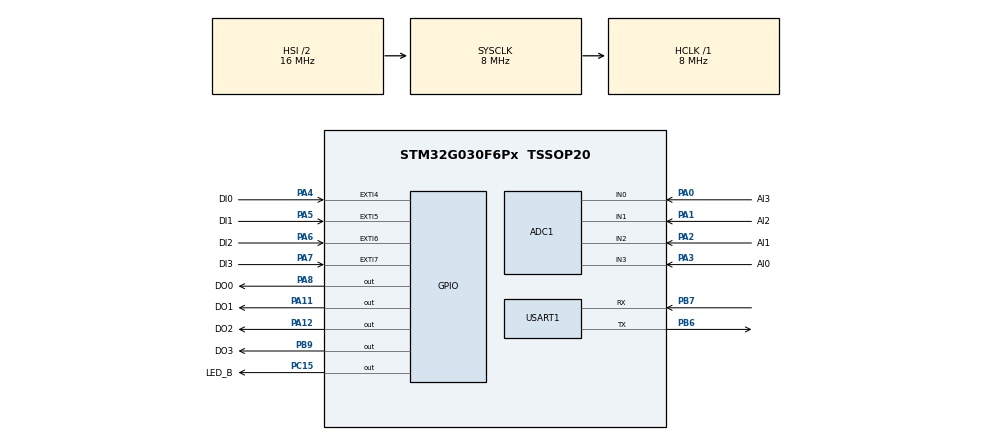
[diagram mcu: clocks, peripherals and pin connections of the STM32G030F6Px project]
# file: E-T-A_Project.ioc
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ADC1.Channel-0\#ChannelRegularConversion=ADC_CHANNEL_0
ADC1.Channel-1\#ChannelRegularConversion=ADC_CHANNEL_1
ADC1.Channel-2\#ChannelRegularConversion=ADC_CHANNEL_2
ADC1.Channel-3\#ChannelRegularConversion=ADC_CHANNEL_3
ADC1.ContinuousConvMode=DISABLE
ADC1.EnableAnalogWatchDog1=false
ADC1.NbrOfConversion=4
ADC1.NbrOfConversionFlag=1
ADC1.Rank-0\#ChannelRegularConversion=1
ADC1.Rank-1\#ChannelRegularConversion=2
ADC1.Rank-2\#ChannelRegularConversion=3
ADC1.Rank-3\#ChannelRegularConversion=4
ADC1.SamplingTime-0\#ChannelRegularConversion=ADC_SAMPLINGTIME_COMMON_1
ADC1.SamplingTime-1\#ChannelRegularConversion=ADC_SAMPLINGTIME_COMMON_1
ADC1.SamplingTime-2\#ChannelRegularConversion=ADC_SAMPLINGTIME_COMMON_1
ADC1.SamplingTime-3\#ChannelRegularConversion=ADC_SAMPLINGTIME_COMMON_1
ADC1.SamplingTimeCommon1=ADC_SAMPLETIME_12CYCLES_5
ADC1.SelectedChannel=ADC_CHANNEL_0|ADC_CHANNEL_1|ADC_CHANNEL_2|ADC_CHANNEL_3
ADC1.master=1
Dma.ADC1.0.Direction=DMA_PERIPH_TO_MEMORY
Dma.ADC1.0.EventEnable=DISABLE
Dma.ADC1.0.Instance=DMA1_Channel1
Dma.ADC1.0.MemDataAlignment=DMA_MDATAALIGN_HALFWORD
Dma.ADC1.0.MemInc=DMA_MINC_ENABLE
Dma.ADC1.0.Mode=DMA_CIRCULAR
Dma.ADC1.0.PeriphDataAlignment=DMA_PDATAALIGN_HALFWORD
Dma.ADC1.0.PeriphInc=DMA_PINC_DISABLE
Dma.ADC1.0.Polarity=HAL_DMAMUX_REQ_GEN_RISING
Dma.ADC1.0.Priority=DMA_PRIORITY_LOW
Dma.ADC1.0.RequestNumber=1
Dma.ADC1.0.SignalID=NONE
Dma.ADC1.0.SyncEnable=ENABLE
Dma.ADC1.0.SyncPolarity=HAL_DMAMUX_SYNC_RISING
Dma.ADC1.0.SyncRequestNumber=1
Dma.ADC1.0.SyncSignalID=HAL_DMAMUX1_SYNC_TIM14_OC
Dma.Request0=ADC1
Dma.Request1=USART1_RX
Dma.USART1_RX.1.Direction=DMA_PERIPH_TO_MEMORY
Dma.USART1_RX.1.EventEnable=DISABLE
Dma.USART1_RX.1.Instance=DMA1_Channel2
Dma.USART1_RX.1.MemDataAlignment=DMA_MDATAALIGN_BYTE
Dma.USART1_RX.1.MemInc=DMA_MINC_ENABLE
Dma.USART1_RX.1.Mode=DMA_CIRCULAR
Dma.USART1_RX.1.PeriphDataAlignment=DMA_PDATAALIGN_BYTE
Dma.USART1_RX.1.PeriphInc=DMA_PINC_DISABLE
Dma.USART1_RX.1.Polarity=HAL_DMAMUX_REQ_GEN_RISING
Dma.USART1_RX.1.Priority=DMA_PRIORITY_LOW
Dma.USART1_RX.1.RequestNumber=1
Dma.USART1_RX.1.SignalID=NONE
Dma.USART1_RX.1.SyncEnable=DISABLE
Dma.USART1_RX.1.SyncPolarity=HAL_DMAMUX_SYNC_NO_EVENT
Dma.USART1_RX.1.SyncRequestNumber=1
Dma.USART1_RX.1.SyncSignalID=NONE
Mcu.Family=STM32G0
Mcu.Name=STM32G030F6Px
Mcu.Package=TSSOP20
NVIC.DMA1_Ch4_5_DMAMUX1_OVR_IRQn=true\:0\:0\:false\:false\:true\:false\:true\:true
NVIC.DMA1_Channel1_IRQn=true\:0\:0\:false\:false\:true\:false\:true\:true
NVIC.DMA1_Channel2_3_IRQn=true\:0\:0\:false\:false\:true\:false\:true\:true
NVIC.EXTI4_15_IRQn=true\:0\:0\:false\:false\:true\:true\:true\:true
PA0.GPIO_Label=AI3
PA0.Mode=IN0
PA0.Signal=ADC1_IN0
PA1.GPIO_Label=AI2
PA1.Mode=IN1
PA1.Signal=ADC1_IN1
PA11\ [PA9].GPIO_Label=DO1
PA11\ [PA9].Signal=GPIO_Output
PA12\ [PA10].GPIO_Label=DO2
PA12\ [PA10].Signal=GPIO_Output
PA13.Mode=Serial_Wire
PA13.Signal=SYS_SWDIO
PA14-BOOT0.Mode=Serial_Wire
PA14-BOOT0.Signal=SYS_SWCLK
PA14-BOOT0__PA15.StandardMode=true
PA2.GPIO_Label=AI1
PA2.Mode=IN2
PA2.Signal=ADC1_IN2
PA3.GPIO_Label=AI0
PA3.Mode=IN3
PA3.Signal=ADC1_IN3
PA4.GPIO_Label=DI0
PA4.Signal=GPXTI4
PA5.GPIO_Label=DI1
PA5.Signal=GPXTI5
PA6.GPIO_Label=DI2
PA6.Signal=GPXTI6
PA7.GPIO_Label=DI3
PA7.Signal=GPXTI7
PA8.GPIO_Label=DO0
PA8.Signal=GPIO_Output
PB0__PB1__PB2__PA8.StandardMode=true
PB3__PB4__PB5__PB6.StandardMode=true
PB6.Mode=Asynchronous
PB6.Signal=USART1_TX
PB7.Mode=Asynchronous
PB7.Signal=USART1_RX
PB7__PB8.StandardMode=true
PB9.GPIO_Label=DO3
PB9.Signal=GPIO_Output
PC14-OSC32_IN\ (PC14)__PB9.StandardMode=true
PC15-OSC32_OUT\ (PC15).GPIO_Label=LED_B
PC15-OSC32_OUT\ (PC15).Signal=GPIO_Output
ProjectManager.HeapSize=0x200
ProjectManager.StackSize=0x400
ProjectManager.TargetToolchain=STM32CubeIDE
RCC.ADCFreq_Value=8000000
RCC.AHBFreq_Value=8000000
RCC.CortexFreq_Value=8000000
RCC.EXTERNAL_CLOCK_VALUE=12288000
RCC.HCLKFreq_Value=8000000
RCC.HSE_VALUE=8000000
RCC.HSISYSCLKDivider=RCC_HSI_DIV2
RCC.HSI_VALUE=16000000
RCC.LSE_VALUE=32768
RCC.SYSCLKFreq_VALUE=8000000
RCC.VCOOutputFreq_Value=128000000
TIM14.Channel=TIM_CHANNEL_1
TIM14.Period=10-1
TIM14.Prescaler=8000-1
TIM14.Pulse=2
USART1.VirtualMode-Asynchronous=VM_ASYNC
VP_TIM14_VS_ClockSourceINT.Mode=Enable_Timer
VP_TIM14_VS_no_output1.Mode=PWM Generation1 No Output
board=custom

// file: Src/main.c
/* USER CODE BEGIN Header */
/**
  ******************************************************************************
  * @file           : main.c
  * @brief          : Main program body
  ******************************************************************************
  * @attention
  *
  * Copyright (c) 2026 STMicroelectronics.
  * All rights reserved.
  *
  * This software is licensed under terms that can be found in the LICENSE file
  * in the root directory of this software component.
  * If no LICENSE file comes with this software, it is provided AS-IS.
  *
  ******************************************************************************
  */
/* USER CODE END Header */
#include "main.h"

/* USER CODE BEGIN Includes */

#include "mainSystemMaster/mainSystem.h"
/* USER CODE END Includes */

ADC_HandleTypeDef hadc1;
DMA_HandleTypeDef hdma_adc1;

TIM_HandleTypeDef htim14;

UART_HandleTypeDef huart1;
DMA_HandleTypeDef hdma_usart1_rx;

void SystemClock_Config(void);
static void MX_GPIO_Init(void);
static void MX_DMA_Init(void);
static void MX_ADC1_Init(void);
static void MX_TIM14_Init(void);
static void MX_USART1_UART_Init(void);

int main(void)
{

  /* MCU Configuration--------------------------------------------------------*/

  /* Reset of all peripherals, Initializes the Flash interface and the Systick. */
  HAL_Init();

  /* Configure the system clock */
  SystemClock_Config();

  /* Initialize all configured peripherals */
  MX_GPIO_Init();
  MX_DMA_Init();
  MX_ADC1_Init();
  MX_TIM14_Init();
  MX_USART1_UART_Init();
  /* USER CODE BEGIN 2 */

  mainSystemBegin();
	Analog_Init();
	UART_Init();

  /* USER CODE END 2 */

  /* Infinite loop */
  while (1)
  {

    /* USER CODE BEGIN 3 */

  	mainSystemLoop();
  	GPIO_Input_Loop();
  	UART_Loop();

  }
  /* USER CODE END 3 */
}

void SystemClock_Config(void)
{
  RCC_OscInitTypeDef RCC_OscInitStruct = {0};
  RCC_ClkInitTypeDef RCC_ClkInitStruct = {0};

  /** Configure the main internal regulator output voltage
  */
  HAL_PWREx_ControlVoltageScaling(PWR_REGULATOR_VOLTAGE_SCALE1);

  /** Initializes the RCC Oscillators according to the specified parameters
  * in the RCC_OscInitTypeDef structure.
  */
  RCC_OscInitStruct.OscillatorType = RCC_OSCILLATORTYPE_HSI;
  RCC_OscInitStruct.HSIState = RCC_HSI_ON;
  RCC_OscInitStruct.HSIDiv = RCC_HSI_DIV2;
  RCC_OscInitStruct.HSICalibrationValue = RCC_HSICALIBRATION_DEFAULT;
  RCC_OscInitStruct.PLL.PLLState = RCC_PLL_NONE;
  if (HAL_RCC_OscConfig(&RCC_OscInitStruct) != HAL_OK)
  {
    Error_Handler();
  }

  /** Initializes the CPU, AHB and APB buses clocks
  */
  RCC_ClkInitStruct.ClockType = RCC_CLOCKTYPE_HCLK|RCC_CLOCKTYPE_SYSCLK
                              |RCC_CLOCKTYPE_PCLK1;
  RCC_ClkInitStruct.SYSCLKSource = RCC_SYSCLKSOURCE_HSI;
  RCC_ClkInitStruct.AHBCLKDivider = RCC_SYSCLK_DIV1;
  RCC_ClkInitStruct.APB1CLKDivider = RCC_HCLK_DIV1;

  if (HAL_RCC_ClockConfig(&RCC_ClkInitStruct, FLASH_LATENCY_0) != HAL_OK)
  {
    Error_Handler();
  }
}

static void MX_ADC1_Init(void)
{

  ADC_ChannelConfTypeDef sConfig = {0};

  /** Configure the global features of the ADC (Clock, Resolution, Data Alignment and number of conversion)
  */
  hadc1.Instance = ADC1;
  hadc1.Init.ClockPrescaler = ADC_CLOCK_SYNC_PCLK_DIV1;
  hadc1.Init.Resolution = ADC_RESOLUTION_12B;
  hadc1.Init.DataAlign = ADC_DATAALIGN_RIGHT;
  hadc1.Init.ScanConvMode = ADC_SCAN_ENABLE;
  hadc1.Init.EOCSelection = ADC_EOC_SINGLE_CONV;
  hadc1.Init.LowPowerAutoWait = DISABLE;
  hadc1.Init.LowPowerAutoPowerOff = DISABLE;
  hadc1.Init.ContinuousConvMode = DISABLE;
  hadc1.Init.NbrOfConversion = 4;
  hadc1.Init.DiscontinuousConvMode = DISABLE;
  hadc1.Init.ExternalTrigConv = ADC_SOFTWARE_START;
  hadc1.Init.ExternalTrigConvEdge = ADC_EXTERNALTRIGCONVEDGE_NONE;
  hadc1.Init.DMAContinuousRequests = DISABLE;
  hadc1.Init.Overrun = ADC_OVR_DATA_PRESERVED;
  hadc1.Init.SamplingTimeCommon1 = ADC_SAMPLETIME_12CYCLES_5;
  hadc1.Init.SamplingTimeCommon2 = ADC_SAMPLETIME_1CYCLE_5;
  hadc1.Init.OversamplingMode = DISABLE;
  hadc1.Init.TriggerFrequencyMode = ADC_TRIGGER_FREQ_HIGH;
  if (HAL_ADC_Init(&hadc1) != HAL_OK)
  {
    Error_Handler();
  }

  /** Configure Regular Channel
  */
  sConfig.Channel = ADC_CHANNEL_0;
  sConfig.Rank = ADC_REGULAR_RANK_1;
  sConfig.SamplingTime = ADC_SAMPLINGTIME_COMMON_1;
  if (HAL_ADC_ConfigChannel(&hadc1, &sConfig) != HAL_OK)
  {
    Error_Handler();
  }

  /** Configure Regular Channel
  */
  sConfig.Channel = ADC_CHANNEL_1;
  sConfig.Rank = ADC_REGULAR_RANK_2;
  if (HAL_ADC_ConfigChannel(&hadc1, &sConfig) != HAL_OK)
  {
    Error_Handler();
  }

  /** Configure Regular Channel
  */
  sConfig.Channel = ADC_CHANNEL_2;
  sConfig.Rank = ADC_REGULAR_RANK_3;
  if (HAL_ADC_ConfigChannel(&hadc1, &sConfig) != HAL_OK)
  {
    Error_Handler();
  }

  /** Configure Regular Channel
  */
  sConfig.Channel = ADC_CHANNEL_3;
  sConfig.Rank = ADC_REGULAR_RANK_4;
  if (HAL_ADC_ConfigChannel(&hadc1, &sConfig) != HAL_OK)
  {
    Error_Handler();
  }

}

static void MX_TIM14_Init(void)
{

  TIM_OC_InitTypeDef sConfigOC = {0};

  htim14.Instance = TIM14;
  htim14.Init.Prescaler = 8000-1;
  htim14.Init.CounterMode = TIM_COUNTERMODE_UP;
  htim14.Init.Period = 10-1;
  htim14.Init.ClockDivision = TIM_CLOCKDIVISION_DIV1;
  htim14.Init.AutoReloadPreload = TIM_AUTORELOAD_PRELOAD_DISABLE;
  if (HAL_TIM_Base_Init(&htim14) != HAL_OK)
  {
    Error_Handler();
  }
  if (HAL_TIM_PWM_Init(&htim14) != HAL_OK)
  {
    Error_Handler();
  }
  sConfigOC.OCMode = TIM_OCMODE_PWM1;
  sConfigOC.Pulse = 2;
  sConfigOC.OCPolarity = TIM_OCPOLARITY_HIGH;
  sConfigOC.OCFastMode = TIM_OCFAST_DISABLE;
  if (HAL_TIM_PWM_ConfigChannel(&htim14, &sConfigOC, TIM_CHANNEL_1) != HAL_OK)
  {
    Error_Handler();
  }

}

static void MX_USART1_UART_Init(void)
{

  huart1.Instance = USART1;
  huart1.Init.BaudRate = 115200;
  huart1.Init.WordLength = UART_WORDLENGTH_8B;
  huart1.Init.StopBits = UART_STOPBITS_1;
  huart1.Init.Parity = UART_PARITY_NONE;
  huart1.Init.Mode = UART_MODE_TX_RX;
  huart1.Init.HwFlowCtl = UART_HWCONTROL_NONE;
  huart1.Init.OverSampling = UART_OVERSAMPLING_16;
  huart1.Init.OneBitSampling = UART_ONE_BIT_SAMPLE_DISABLE;
  huart1.Init.ClockPrescaler = UART_PRESCALER_DIV1;
  huart1.AdvancedInit.AdvFeatureInit = UART_ADVFEATURE_NO_INIT;
  if (HAL_UART_Init(&huart1) != HAL_OK)
  {
    Error_Handler();
  }
  if (HAL_UARTEx_SetTxFifoThreshold(&huart1, UART_TXFIFO_THRESHOLD_1_8) != HAL_OK)
  {
    Error_Handler();
  }
  if (HAL_UARTEx_SetRxFifoThreshold(&huart1, UART_RXFIFO_THRESHOLD_1_8) != HAL_OK)
  {
    Error_Handler();
  }
  if (HAL_UARTEx_DisableFifoMode(&huart1) != HAL_OK)
  {
    Error_Handler();
  }

}

static void MX_DMA_Init(void)
{

  /* DMA controller clock enable */
  __HAL_RCC_DMA1_CLK_ENABLE();

  /* DMA interrupt init */
  /* DMA1_Channel1_IRQn interrupt configuration */
  HAL_NVIC_SetPriority(DMA1_Channel1_IRQn, 0, 0);
  HAL_NVIC_EnableIRQ(DMA1_Channel1_IRQn);
  /* DMA1_Channel2_3_IRQn interrupt configuration */
  HAL_NVIC_SetPriority(DMA1_Channel2_3_IRQn, 0, 0);
  HAL_NVIC_EnableIRQ(DMA1_Channel2_3_IRQn);
  /* DMA1_Ch4_5_DMAMUX1_OVR_IRQn interrupt configuration */
  HAL_NVIC_SetPriority(DMA1_Ch4_5_DMAMUX1_OVR_IRQn, 0, 0);
  HAL_NVIC_EnableIRQ(DMA1_Ch4_5_DMAMUX1_OVR_IRQn);

}

static void MX_GPIO_Init(void)
{
  GPIO_InitTypeDef GPIO_InitStruct = {0};

  /* GPIO Ports Clock Enable */
  __HAL_RCC_GPIOB_CLK_ENABLE();
  __HAL_RCC_GPIOC_CLK_ENABLE();
  __HAL_RCC_GPIOA_CLK_ENABLE();

  /*Configure GPIO pin Output Level */
  HAL_GPIO_WritePin(DO3_GPIO_Port, DO3_Pin, GPIO_PIN_RESET);

  /*Configure GPIO pin Output Level */
  HAL_GPIO_WritePin(LED_B_GPIO_Port, LED_B_Pin, GPIO_PIN_RESET);

  /*Configure GPIO pin Output Level */
  HAL_GPIO_WritePin(GPIOA, DO0_Pin|DO1_Pin|DO2_Pin, GPIO_PIN_RESET);

  /*Configure GPIO pin : DO3_Pin */
  GPIO_InitStruct.Pin = DO3_Pin;
  GPIO_InitStruct.Mode = GPIO_MODE_OUTPUT_PP;
  GPIO_InitStruct.Pull = GPIO_NOPULL;
  GPIO_InitStruct.Speed = GPIO_SPEED_FREQ_LOW;
  HAL_GPIO_Init(DO3_GPIO_Port, &GPIO_InitStruct);

  /*Configure GPIO pin : LED_B_Pin */
  GPIO_InitStruct.Pin = LED_B_Pin;
  GPIO_InitStruct.Mode = GPIO_MODE_OUTPUT_PP;
  GPIO_InitStruct.Pull = GPIO_NOPULL;
  GPIO_InitStruct.Speed = GPIO_SPEED_FREQ_LOW;
  HAL_GPIO_Init(LED_B_GPIO_Port, &GPIO_InitStruct);

  /*Configure GPIO pins : DI0_Pin DI1_Pin DI2_Pin DI3_Pin */
  GPIO_InitStruct.Pin = DI0_Pin|DI1_Pin|DI2_Pin|DI3_Pin;
  GPIO_InitStruct.Mode = GPIO_MODE_IT_RISING;
  GPIO_InitStruct.Pull = GPIO_NOPULL;
  HAL_GPIO_Init(GPIOA, &GPIO_InitStruct);

  /*Configure GPIO pins : DO0_Pin DO1_Pin DO2_Pin */
  GPIO_InitStruct.Pin = DO0_Pin|DO1_Pin|DO2_Pin;
  GPIO_InitStruct.Mode = GPIO_MODE_OUTPUT_PP;
  GPIO_InitStruct.Pull = GPIO_NOPULL;
  GPIO_InitStruct.Speed = GPIO_SPEED_FREQ_LOW;
  HAL_GPIO_Init(GPIOA, &GPIO_InitStruct);

  /* EXTI interrupt init*/
  HAL_NVIC_SetPriority(EXTI4_15_IRQn, 0, 0);
  HAL_NVIC_EnableIRQ(EXTI4_15_IRQn);

}

void Error_Handler(void)
{
  __disable_irq();
  while (1)
  {
  }
}
